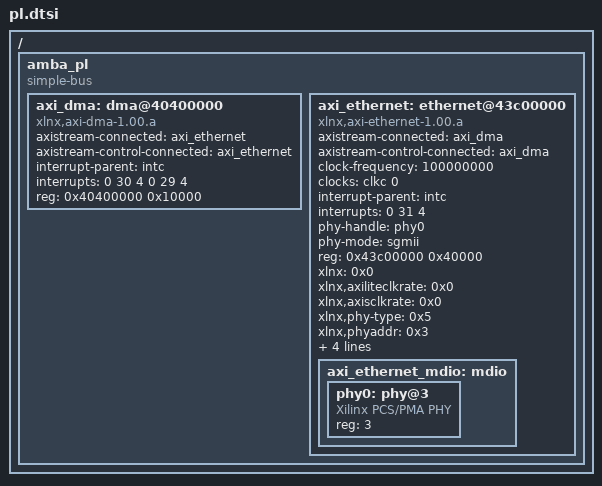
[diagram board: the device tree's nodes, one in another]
/*
 * CAUTION: This file is automatically generated by Xilinx.
 * Version: HSI 2015.4
 * Today is: Tue Jun 18 17:26:37 2019
*/


/ {
	amba_pl: amba_pl {
		#address-cells = <1>;
		#size-cells = <1>;
		compatible = "simple-bus";
		ranges ;
		axi_dma: dma@40400000 {
			#dma-cells = <1>;
			axistream-connected = <&axi_ethernet>;
			axistream-control-connected = <&axi_ethernet>;
			compatible = "xlnx,axi-dma-1.00.a";
			interrupt-parent = <&intc>;
			interrupts = <0 30 4 0 29 4>;
			reg = <0x40400000 0x10000>;
		};
		axi_ethernet: ethernet@43c00000 {
			axistream-connected = <&axi_dma>;
			axistream-control-connected = <&axi_dma>;
			clock-frequency = <100000000>;
			clock-names = "ref_clk";
			clocks = <&clkc 0>;
			compatible = "xlnx,axi-ethernet-1.00.a";
			device_type = "network";
			interrupt-parent = <&intc>;
			interrupts = <0 31 4>;
			phy-handle = <&phy0>;
			phy-mode = "sgmii";
			reg = <0x43c00000 0x40000>;
			xlnx = <0x0>;
			xlnx,axiliteclkrate = <0x0>;
			xlnx,axisclkrate = <0x0>;
			xlnx,phy-type = <0x5>;
			xlnx,phyaddr = <0x3>;
			xlnx,rable = <0x0>;
			xlnx,rxcsum = <0x2>;
			xlnx,rxmem = <0x4000>;
			xlnx,txcsum = <0x2>;
			axi_ethernet_mdio: mdio {
				#address-cells = <1>;
				#size-cells = <0>;
				phy0: phy@3 {
					compatible = "Xilinx PCS/PMA PHY";
					device_type = "ethernet-phy";
					reg = <3>;
				};
			};
		};
	};
};
